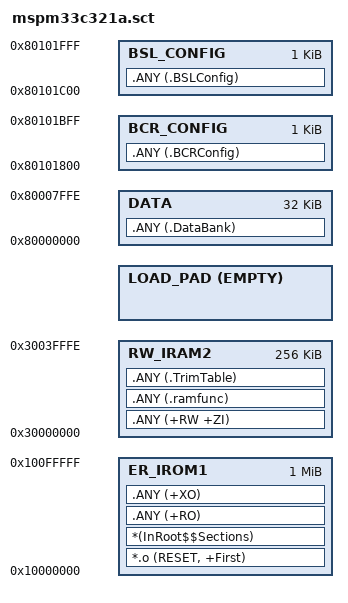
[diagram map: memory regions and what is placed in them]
; *************************************************************
; *** Scatter-Loading Description File generated by uVision ***
; *************************************************************

LR_IROM1 0x10000000 0x00100000  {    ; load region size_region
  ER_IROM1 0x10000000 ALIGNALL 16 0x00100000 {  ; load address = execution address
   *.o (RESET, +First)
   *(InRoot$$Sections)
   .ANY (+RO)
   .ANY (+XO)
  }
  RW_IRAM2 0x30000000 0x0003FFFF  {  ; RW data
   .ANY (+RW +ZI)
   .ANY (.ramfunc)
   .ANY (.TrimTable)
  }
  ; Pad flash load image to 16-byte boundary for 128-bit word flash programming
  LOAD_PAD +0 ALIGN 16 EMPTY 0x0 {}
}

LR_DATA 0x80000000 0x00007FFF  {    ; load region size_region
   DATA 0x80000000 0x00007FFF{
    .ANY (.DataBank)
  }
}

LR_BCR 0x80101800 0x00000400  {    ; load region size_region
  BCR_CONFIG 0x80101800 0x00000400{
    .ANY (.BCRConfig)
  }
}

LR_BSL 0x80101C00 0x00000400  {    ; load region size_region
   BSL_CONFIG 0x80101C00 0x00000400{
    .ANY (.BSLConfig)
  }
}
